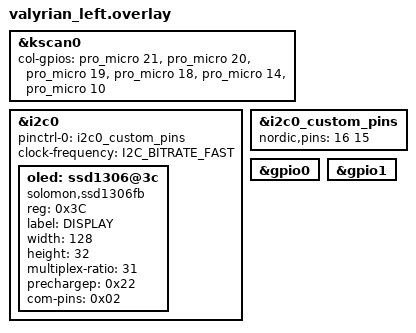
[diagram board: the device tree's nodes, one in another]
#include "valyrian.dtsi" 

&kscan0 {
    col-gpios
        = <&pro_micro 21 GPIO_ACTIVE_HIGH>
        , <&pro_micro 20 GPIO_ACTIVE_HIGH>
        , <&pro_micro 19 GPIO_ACTIVE_HIGH>
        , <&pro_micro 18 GPIO_ACTIVE_HIGH>
        , <&pro_micro 14 GPIO_ACTIVE_HIGH>
        , <&pro_micro 10 GPIO_ACTIVE_HIGH>
        ;
};

&i2c0 {
    status = "okay";

    pinctrl-0 = <&i2c0_custom_pins>;
    pinctrl-names = "default";

    clock-frequency = <I2C_BITRATE_FAST>;

    oled: ssd1306@3c {
        compatible = "solomon,ssd1306fb";
        reg = <0x3C>;
        label = "DISPLAY";

        width = <128>;
        height = <32>;

        multiplex-ratio = <31>;
        prechargep = <0x22>;
        com-pins = <0x02>;
    };
};

/* Pin control for custom SDA/SCL */
&i2c0_custom_pins {
    nordic,pins = <
        16  /* SDA pin number */
        15  /* SCL pin number */
    >;
};

&gpio0 {
    status = "okay";
};

&gpio1 {
    status = "okay";
};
